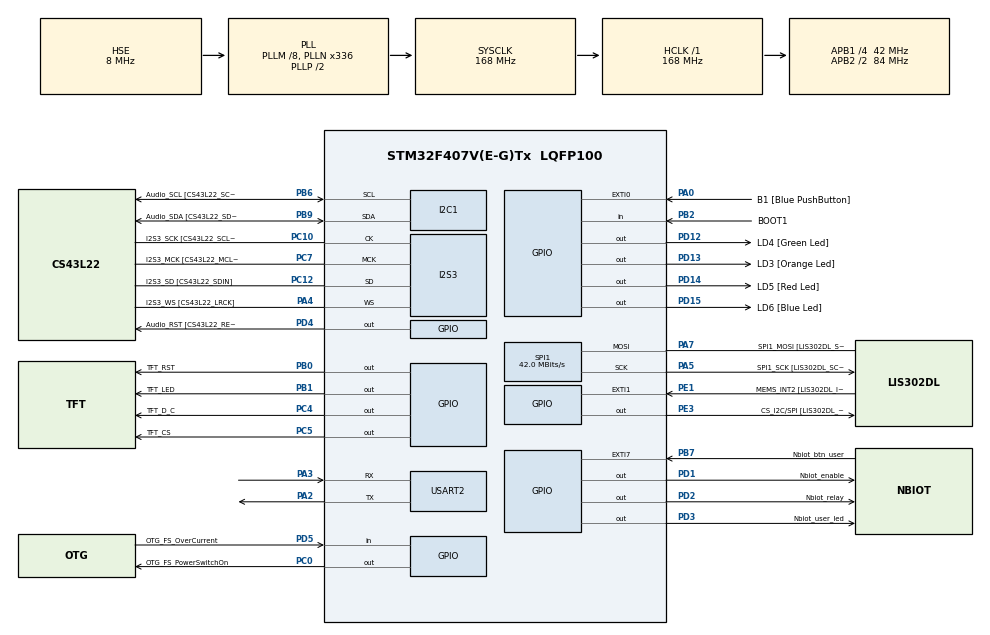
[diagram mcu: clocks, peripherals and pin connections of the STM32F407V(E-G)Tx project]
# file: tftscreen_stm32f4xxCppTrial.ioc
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I2S3.AudioFreq-Half_Duplex_Master=I2S_AUDIOFREQ_96K
I2S3.ErrorAudioFreq=-2.34 %
I2S3.ErrorAudioFreq-Half_Duplex_Master=0.8 %
I2S3.FullDuplexMode=I2S_FULLDUPLEXMODE_DISABLE
I2S3.Instance=SPI$Index
I2S3.RealAudioFreq=93.75 KHz
I2S3.RealAudioFreq-Half_Duplex_Master=96.774 KHz
I2S3.VirtualMode=I2S_MODE_MASTER
Mcu.Family=STM32F4
Mcu.Name=STM32F407V(E-G)Tx
Mcu.Package=LQFP100
NVIC.EXTI9_5_IRQn=true\:0\:0\:false\:false\:true\:true
NVIC.FLASH_IRQn=true\:0\:0\:false\:false\:true\:true
NVIC.FPU_IRQn=true\:0\:0\:false\:false\:true\:true
NVIC.HASH_RNG_IRQn=true\:0\:0\:false\:false\:true\:true
NVIC.I2C1_ER_IRQn=true\:0\:0\:false\:false\:true\:true
NVIC.I2C1_EV_IRQn=true\:0\:0\:false\:false\:true\:true
NVIC.PVD_IRQn=true\:0\:0\:false\:false\:true\:true
NVIC.PriorityGroup=NVIC_PRIORITYGROUP_0
NVIC.RCC_IRQn=true\:0\:0\:false\:false\:true\:true
NVIC.SPI1_IRQn=true\:0\:0\:false\:false\:true\:true
NVIC.SPI3_IRQn=true\:0\:0\:false\:false\:true\:true
NVIC.TIM1_BRK_TIM9_IRQn=true\:0\:0\:false\:false\:true\:true
NVIC.TIM1_CC_IRQn=true\:0\:0\:false\:false\:true\:true
NVIC.TIM1_TRG_COM_TIM11_IRQn=true\:0\:0\:false\:false\:true\:true
NVIC.TIM1_UP_TIM10_IRQn=true\:0\:0\:false\:false\:true\:true
NVIC.TIM2_IRQn=true\:0\:0\:false\:false\:true\:true
NVIC.TIM3_IRQn=true\:0\:0\:false\:false\:true\:true
NVIC.TIM4_IRQn=true\:0\:0\:false\:false\:true\:true
NVIC.TIM5_IRQn=true\:0\:0\:false\:false\:true\:true
NVIC.TIM6_DAC_IRQn=true\:0\:0\:false\:false\:true\:true
NVIC.TIM7_IRQn=true\:0\:0\:false\:false\:true\:true
NVIC.TIM8_BRK_TIM12_IRQn=true\:0\:0\:false\:false\:true\:true
NVIC.TIM8_CC_IRQn=true\:0\:0\:false\:false\:true\:true
NVIC.TIM8_TRG_COM_TIM14_IRQn=true\:0\:0\:false\:false\:true\:true
NVIC.TIM8_UP_TIM13_IRQn=true\:0\:0\:false\:false\:true\:true
NVIC.USART2_IRQn=true\:0\:0\:false\:false\:true\:true
PA0-WKUP.GPIO_Label=B1 [Blue PushButton]
PA0-WKUP.GPIO_ModeDefaultEXTI=GPIO_MODE_EVT_RISING
PA0-WKUP.GPIO_PuPd=GPIO_NOPULL
PA0-WKUP.Signal=GPXTI0
PA10.GPIO_Label=OTG_FS_ID
PA10.GPIO_Mode=GPIO_MODE_AF_PP
PA10.GPIO_PuPd=GPIO_NOPULL
PA10.GPIO_Speed=GPIO_SPEED_FREQ_LOW
PA10.Signal=USB_OTG_FS_ID
PA11.GPIO_Label=OTG_FS_DM
PA11.GPIO_Mode=GPIO_MODE_AF_PP
PA11.GPIO_PuPd=GPIO_NOPULL
PA11.GPIO_Speed=GPIO_SPEED_FREQ_LOW
PA11.Signal=USB_OTG_FS_DM
PA12.GPIO_Label=OTG_FS_DP
PA12.GPIO_Mode=GPIO_MODE_AF_PP
PA12.GPIO_PuPd=GPIO_NOPULL
PA12.GPIO_Speed=GPIO_SPEED_FREQ_LOW
PA12.Signal=USB_OTG_FS_DP
PA13.GPIO_Label=SWDIO
PA13.Mode=Serial_Wire
PA13.Signal=SYS_JTMS-SWDIO
PA14.GPIO_Label=SWCLK
PA14.Mode=Serial_Wire
PA14.Signal=SYS_JTCK-SWCLK
PA2.Mode=Asynchronous
PA2.Signal=USART2_TX
PA3.Mode=Asynchronous
PA3.Signal=USART2_RX
PA4.GPIO_Label=I2S3_WS [CS43L22_LRCK]
PA4.GPIO_Mode=GPIO_MODE_AF_PP
PA4.GPIO_PuPd=GPIO_NOPULL
PA4.GPIO_Speed=GPIO_SPEED_FREQ_LOW
PA4.Mode=Half_Duplex_Master
PA4.Signal=I2S3_WS
PA5.GPIO_Label=SPI1_SCK [LIS302DL_SCL/SPC]
PA5.GPIO_Mode=GPIO_MODE_AF_PP
PA5.GPIO_PuPd=GPIO_NOPULL
PA5.GPIO_Speed=GPIO_SPEED_FREQ_LOW
PA5.Mode=Simplex_Bidirectional_Master
PA5.Signal=SPI1_SCK
PA6.GPIO_Label=SPI1_MISO [LIS302DL_SDO]
PA6.GPIO_Mode=GPIO_MODE_AF_PP
PA6.GPIO_PuPd=GPIO_NOPULL
PA6.GPIO_Speed=GPIO_SPEED_FREQ_LOW
PA6.Signal=SPI1_MISO
PA7.GPIO_Label=SPI1_MOSI [LIS302DL_SDA/SDI/SDO]
PA7.GPIO_Mode=GPIO_MODE_AF_PP
PA7.GPIO_PuPd=GPIO_NOPULL
PA7.GPIO_Speed=GPIO_SPEED_FREQ_LOW
PA7.Mode=Simplex_Bidirectional_Master
PA7.Signal=SPI1_MOSI
PA9.GPIO_Label=VBUS_FS
PA9.GPIO_Mode=GPIO_MODE_INPUT
PA9.GPIO_PuPd=GPIO_NOPULL
PA9.Signal=USB_OTG_FS_VBUS
PB0.GPIO_Label=TFT_RST
PB0.Signal=GPIO_Output
PB1.GPIO_Label=TFT_LED
PB1.Signal=GPIO_Output
PB10.GPIO_Label=CLK_IN [MP45DT02_CLK]
PB10.GPIO_Mode=GPIO_MODE_AF_PP
PB10.GPIO_PuPd=GPIO_NOPULL
PB10.GPIO_Speed=GPIO_SPEED_FREQ_LOW
PB10.Signal=I2S2_CK
PB2.GPIO_Label=BOOT1
PB2.GPIO_Mode=GPIO_MODE_INPUT
PB2.GPIO_PuPd=GPIO_NOPULL
PB2.Signal=GPIO_Input
PB3.GPIO_Label=SWO
PB3.Signal=SYS_JTDO-SWO
PB6.GPIO_Label=Audio_SCL [CS43L22_SCL]
PB6.GPIO_Mode=GPIO_MODE_AF_OD
PB6.GPIO_PuPd=GPIO_NOPULL
PB6.GPIO_Speed=GPIO_SPEED_FREQ_LOW
PB6.Mode=I2C
PB6.Signal=I2C1_SCL
PB7.GPIO_Label=Nbiot_btn_user
PB7.Signal=GPXTI7
PB9.GPIO_Label=Audio_SDA [CS43L22_SDA]
PB9.GPIO_Mode=GPIO_MODE_AF_OD
PB9.GPIO_PuPd=GPIO_NOPULL
PB9.GPIO_Speed=GPIO_SPEED_FREQ_LOW
PB9.Mode=I2C
PB9.Signal=I2C1_SDA
PC0.GPIO_Label=OTG_FS_PowerSwitchOn
PC0.GPIO_PuPd=GPIO_NOPULL
PC0.GPIO_Speed=GPIO_SPEED_FREQ_LOW
PC0.PinState=GPIO_PIN_SET
PC0.Signal=GPIO_Output
PC10.GPIO_Label=I2S3_SCK [CS43L22_SCLK]
PC10.GPIO_Mode=GPIO_MODE_AF_PP
PC10.GPIO_PuPd=GPIO_NOPULL
PC10.GPIO_Speed=GPIO_SPEED_FREQ_LOW
PC10.Mode=Half_Duplex_Master
PC10.Signal=I2S3_CK
PC12.GPIO_Label=I2S3_SD [CS43L22_SDIN]
PC12.GPIO_Mode=GPIO_MODE_AF_PP
PC12.GPIO_PuPd=GPIO_NOPULL
PC12.GPIO_Speed=GPIO_SPEED_FREQ_LOW
PC12.Mode=Half_Duplex_Master
PC12.Signal=I2S3_SD
PC14-OSC32_IN.GPIO_Label=PC14-OSC32_IN
PC14-OSC32_IN.Mode=LSE-External-Oscillator
PC14-OSC32_IN.Signal=RCC_OSC32_IN
PC15-OSC32_OUT.GPIO_Label=PC15-OSC32_OUT
PC15-OSC32_OUT.Mode=LSE-External-Oscillator
PC15-OSC32_OUT.Signal=RCC_OSC32_OUT
PC3.GPIO_Label=PDM_OUT [MP45DT02_DOUT]
PC3.GPIO_Mode=GPIO_MODE_AF_PP
PC3.GPIO_PuPd=GPIO_NOPULL
PC3.GPIO_Speed=GPIO_SPEED_FREQ_LOW
PC3.Signal=I2S2_SD
PC4.GPIO_Label=TFT_D_C
PC4.Signal=GPIO_Output
PC5.GPIO_Label=TFT_CS
PC5.Signal=GPIO_Output
PC7.GPIO_Label=I2S3_MCK [CS43L22_MCLK]
PC7.GPIO_Mode=GPIO_MODE_AF_PP
PC7.GPIO_PuPd=GPIO_NOPULL
PC7.GPIO_Speed=GPIO_SPEED_FREQ_LOW
PC7.Mode=Master_Clock_Activated
PC7.Signal=I2S3_MCK
PD1.GPIO_Label=Nbiot_enable
PD1.Signal=GPIO_Output
PD12.GPIO_Label=LD4 [Green Led]
PD12.GPIO_PuPd=GPIO_NOPULL
PD12.GPIO_Speed=GPIO_SPEED_FREQ_LOW
PD12.Signal=GPIO_Output
PD13.GPIO_Label=LD3 [Orange Led]
PD13.GPIO_PuPd=GPIO_NOPULL
PD13.GPIO_Speed=GPIO_SPEED_FREQ_LOW
PD13.Signal=GPIO_Output
PD14.GPIO_Label=LD5 [Red Led]
PD14.GPIO_PuPd=GPIO_NOPULL
PD14.GPIO_Speed=GPIO_SPEED_FREQ_LOW
PD14.Signal=GPIO_Output
PD15.GPIO_Label=LD6 [Blue Led]
PD15.GPIO_PuPd=GPIO_NOPULL
PD15.GPIO_Speed=GPIO_SPEED_FREQ_LOW
PD15.Signal=GPIO_Output
PD2.GPIO_Label=Nbiot_relay
PD2.Signal=GPIO_Output
PD3.GPIO_Label=Nbiot_user_led
PD3.Signal=GPIO_Output
PD4.GPIO_Label=Audio_RST [CS43L22_RESET]
PD4.GPIO_PuPd=GPIO_NOPULL
PD4.GPIO_Speed=GPIO_SPEED_FREQ_LOW
PD4.Signal=GPIO_Output
PD5.GPIO_Label=OTG_FS_OverCurrent
PD5.GPIO_Mode=GPIO_MODE_INPUT
PD5.GPIO_PuPd=GPIO_NOPULL
PD5.Signal=GPIO_Input
PE1.GPIO_Label=MEMS_INT2 [LIS302DL_INT2]
PE1.GPIO_ModeDefaultEXTI=GPIO_MODE_EVT_RISING
PE1.GPIO_PuPd=GPIO_NOPULL
PE1.Signal=GPXTI1
PE3.GPIO_Label=CS_I2C/SPI [LIS302DL_CS_I2C/SPI]
PE3.GPIO_PuPd=GPIO_NOPULL
PE3.GPIO_Speed=GPIO_SPEED_FREQ_LOW
PE3.Signal=GPIO_Output
PH0-OSC_IN.GPIO_Label=PH0-OSC_IN
PH0-OSC_IN.Mode=HSE-External-Oscillator
PH0-OSC_IN.Signal=RCC_OSC_IN
PH1-OSC_OUT.GPIO_Label=PH1-OSC_OUT
PH1-OSC_OUT.Mode=HSE-External-Oscillator
PH1-OSC_OUT.Signal=RCC_OSC_OUT
ProjectManager.HeapSize=0x200
ProjectManager.StackSize=0x400
ProjectManager.TargetToolchain=MDK-ARM V5
RCC.48MHZClocksFreq_Value=48000000
RCC.AHBFreq_Value=168000000
RCC.APB1CLKDivider=RCC_HCLK_DIV4
RCC.APB1Freq_Value=42000000
RCC.APB1TimFreq_Value=84000000
RCC.APB2CLKDivider=RCC_HCLK_DIV2
RCC.APB2Freq_Value=84000000
RCC.APB2TimFreq_Value=168000000
RCC.CortexFreq_Value=168000000
RCC.HCLKFreq_Value=168000000
RCC.HSE_VALUE=8000000
RCC.HSI_VALUE=16000000
RCC.PLLM=8
RCC.PLLN=336
RCC.PLLQ=7
RCC.PLLSourceVirtual=RCC_PLLSOURCE_HSE
RCC.SYSCLKFreq_VALUE=168000000
RCC.SYSCLKSource=RCC_SYSCLKSOURCE_PLLCLK
RCC.VCOOutputFreq_Value=336000000
SPI1.CLKPhase=SPI_PHASE_2EDGE
SPI1.CalculateBaudRate=42.0 MBits/s
SPI1.Direction=SPI_DIRECTION_1LINE
SPI1.Mode=SPI_MODE_MASTER
SPI1.VirtualType=VM_MASTER
USART2.VirtualMode=VM_ASYNC
VP_RNG_VS_RNG.Mode=RNG_Activate
VP_TIM10_VS_ClockSourceINT.Mode=Enable_Timer
VP_TIM11_VS_ClockSourceINT.Mode=Enable_Timer
VP_TIM12_VS_ClockSourceINT.Mode=Internal
VP_TIM13_VS_ClockSourceINT.Mode=Enable_Timer
VP_TIM14_VS_ClockSourceINT.Mode=Enable_Timer
VP_TIM1_VS_ClockSourceINT.Mode=Internal
VP_TIM2_VS_ClockSourceINT.Mode=Internal
VP_TIM3_VS_ClockSourceINT.Mode=Internal
VP_TIM4_VS_ClockSourceINT.Mode=Internal
VP_TIM5_VS_ClockSourceINT.Mode=Internal
VP_TIM6_VS_ClockSourceINT.Mode=Enable_Timer
VP_TIM7_VS_ClockSourceINT.Mode=Enable_Timer
VP_TIM8_VS_ClockSourceINT.Mode=Internal
VP_TIM9_VS_ClockSourceINT.Mode=Internal
board=STM32F4DISCOVERY

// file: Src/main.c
/**
  ******************************************************************************
  * @file           : main.c
  * @brief          : Main program body
  ******************************************************************************
  ** This notice applies to any and all portions of this file
  * that are not between comment pairs USER CODE BEGIN and
  * USER CODE END. Other portions of this file, whether
  * inserted by the user or by software development tools
  * are owned by their respective copyright owners.
  *
  * COPYRIGHT(c) 2018 STMicroelectronics
  *
  * Redistribution and use in source and binary forms, with or without modification,
  * are permitted provided that the following conditions are met:
  *   1. Redistributions of source code must retain the above copyright notice,
  *      this list of conditions and the following disclaimer.
  *   2. Redistributions in binary form must reproduce the above copyright notice,
  *      this list of conditions and the following disclaimer in the documentation
  *      and/or other materials provided with the distribution.
  *   3. Neither the name of STMicroelectronics nor the names of its contributors
  *      may be used to endorse or promote products derived from this software
  *      without specific prior written permission.
  *
  * THIS SOFTWARE IS PROVIDED BY THE COPYRIGHT HOLDERS AND CONTRIBUTORS "AS IS"
  * AND ANY EXPRESS OR IMPLIED WARRANTIES, INCLUDING, BUT NOT LIMITED TO, THE
  * IMPLIED WARRANTIES OF MERCHANTABILITY AND FITNESS FOR A PARTICULAR PURPOSE ARE
  * DISCLAIMED. IN NO EVENT SHALL THE COPYRIGHT HOLDER OR CONTRIBUTORS BE LIABLE
  * FOR ANY DIRECT, INDIRECT, INCIDENTAL, SPECIAL, EXEMPLARY, OR CONSEQUENTIAL
  * DAMAGES (INCLUDING, BUT NOT LIMITED TO, PROCUREMENT OF SUBSTITUTE GOODS OR
  * SERVICES; LOSS OF USE, DATA, OR PROFITS; OR BUSINESS INTERRUPTION) HOWEVER
  * CAUSED AND ON ANY THEORY OF LIABILITY, WHETHER IN CONTRACT, STRICT LIABILITY,
  * OR TORT (INCLUDING NEGLIGENCE OR OTHERWISE) ARISING IN ANY WAY OUT OF THE USE
  * OF THIS SOFTWARE, EVEN IF ADVISED OF THE POSSIBILITY OF SUCH DAMAGE.
  *
  ******************************************************************************
  */
#include "main.h"
#include "stm32f4xx_hal.h"
#include "i2c.h"
#include "i2s.h"
#include "rng.h"
#include "spi.h"
#include "tim.h"
#include "usart.h"
#include "gpio.h"

/* USER CODE BEGIN Includes */
#include "ILI9341_GFX.h"
#include "ILI9341_STM32_Driver.h"
/* USER CODE END Includes */

/* USER CODE BEGIN PV */
/* Private variables ---------------------------------------------------------*/

/* USER CODE END PV */

void SystemClock_Config(void);

/* USER CODE BEGIN PFP */
/* Private function prototypes -----------------------------------------------*/

/* USER CODE END PFP */

int main(void)
{

  /* MCU Configuration----------------------------------------------------------*/

  /* Reset of all peripherals, Initializes the Flash interface and the Systick. */
  HAL_Init();

  /* Configure the system clock */
  SystemClock_Config();

  /* Initialize all configured peripherals */
  MX_GPIO_Init();
  MX_I2S3_Init();
  MX_SPI1_Init();
  MX_TIM9_Init();
  MX_TIM10_Init();
  MX_TIM11_Init();
  MX_TIM12_Init();
  MX_I2C1_Init();
  MX_USART2_UART_Init();
  MX_RNG_Init();
  MX_TIM1_Init();
  MX_TIM2_Init();
  MX_TIM3_Init();
  MX_TIM4_Init();
  MX_TIM5_Init();
  MX_TIM6_Init();
  MX_TIM7_Init();
  MX_TIM8_Init();
  MX_TIM13_Init();
  MX_TIM14_Init();

  /* Infinite loop */
  while (1)
  {

  }

}

void SystemClock_Config(void)
{

  RCC_OscInitTypeDef RCC_OscInitStruct;
  RCC_ClkInitTypeDef RCC_ClkInitStruct;
  RCC_PeriphCLKInitTypeDef PeriphClkInitStruct;

    /**Configure the main internal regulator output voltage
    */
  __HAL_RCC_PWR_CLK_ENABLE();

  __HAL_PWR_VOLTAGESCALING_CONFIG(PWR_REGULATOR_VOLTAGE_SCALE1);

    /**Initializes the CPU, AHB and APB busses clocks
    */
  RCC_OscInitStruct.OscillatorType = RCC_OSCILLATORTYPE_HSE;
  RCC_OscInitStruct.HSEState = RCC_HSE_ON;
  RCC_OscInitStruct.PLL.PLLState = RCC_PLL_ON;
  RCC_OscInitStruct.PLL.PLLSource = RCC_PLLSOURCE_HSE;
  RCC_OscInitStruct.PLL.PLLM = 8;
  RCC_OscInitStruct.PLL.PLLN = 336;
  RCC_OscInitStruct.PLL.PLLP = RCC_PLLP_DIV2;
  RCC_OscInitStruct.PLL.PLLQ = 7;
  if (HAL_RCC_OscConfig(&RCC_OscInitStruct) != HAL_OK)
  {
    _Error_Handler(__FILE__, __LINE__);
  }

    /**Initializes the CPU, AHB and APB busses clocks
    */
  RCC_ClkInitStruct.ClockType = RCC_CLOCKTYPE_HCLK|RCC_CLOCKTYPE_SYSCLK
                              |RCC_CLOCKTYPE_PCLK1|RCC_CLOCKTYPE_PCLK2;
  RCC_ClkInitStruct.SYSCLKSource = RCC_SYSCLKSOURCE_PLLCLK;
  RCC_ClkInitStruct.AHBCLKDivider = RCC_SYSCLK_DIV1;
  RCC_ClkInitStruct.APB1CLKDivider = RCC_HCLK_DIV4;
  RCC_ClkInitStruct.APB2CLKDivider = RCC_HCLK_DIV2;

  if (HAL_RCC_ClockConfig(&RCC_ClkInitStruct, FLASH_LATENCY_5) != HAL_OK)
  {
    _Error_Handler(__FILE__, __LINE__);
  }

  PeriphClkInitStruct.PeriphClockSelection = RCC_PERIPHCLK_I2S;
  PeriphClkInitStruct.PLLI2S.PLLI2SN = 192;
  PeriphClkInitStruct.PLLI2S.PLLI2SR = 2;
  if (HAL_RCCEx_PeriphCLKConfig(&PeriphClkInitStruct) != HAL_OK)
  {
    _Error_Handler(__FILE__, __LINE__);
  }

    /**Configure the Systick interrupt time
    */
  HAL_SYSTICK_Config(HAL_RCC_GetHCLKFreq()/1000);

    /**Configure the Systick
    */
  HAL_SYSTICK_CLKSourceConfig(SYSTICK_CLKSOURCE_HCLK);

  /* SysTick_IRQn interrupt configuration */
  HAL_NVIC_SetPriority(SysTick_IRQn, 0, 0);
}

void _Error_Handler(char *file, int line)
{
  while(1)
  {
  }
}

/************************ (C) COPYRIGHT STMicroelectronics *****END OF FILE****/
